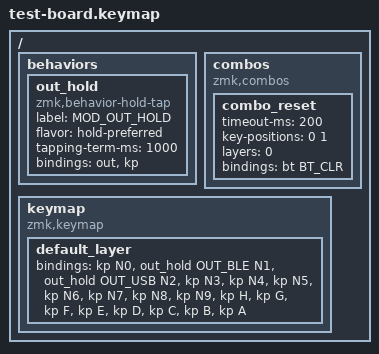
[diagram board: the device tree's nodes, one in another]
/*
 * Copyright (c) 2022 beta-tank
 * SPDX-License-Identifier: MIT
 */

 #include <behaviors.dtsi>
 #include <dt-bindings/zmk/keys.h>
 #include <dt-bindings/zmk/bt.h>
 #include <dt-bindings/zmk/outputs.h>

 /*

 Tap combo "0" and "1" for BT pairing reset

 LEGEND: KEYCODE | NRFMICRO_PIN (ARDUINO_PIN)

 - | RAW          (1) 0.06 | 0
 - | GND          (0) 0.08 | 1
 - | RST              GND  | -
 - | VCC              GND  | -
 A | 0.30 (21)    (2) 0.15 | 2
 B | 0.31 (20)    (3) 0.17 | 3
 C | 0.29 (19)    (4) 0.20 | 4
 D | 0.02 (18)    (5) 0.13 | 5
 E | 1.13 (15)    (6) 0.24 | 6
 F | 0.03 (14)    (7) 0.09 | 7
 G | 0.28 (16)    (8) 0.10 | 8
 H | 1.11 (10)    (9) 1.06 | 9 
 
 */
 
 / {
        behaviors {
                out_hold: out_hold {
                        compatible = "zmk,behavior-hold-tap";
                        label = "MOD_OUT_HOLD";
                        #binding-cells = <2>;
                        flavor = "hold-preferred";
                        tapping-term-ms = <1000>;
                        bindings = <&out>, <&kp>; //<&bt BT_CLR>
                };
        };
        combos {
                compatible = "zmk,combos";
                combo_reset {
                    timeout-ms = <200>;
                    key-positions = <0 1>;
                    layers = <0>;
                    bindings = <&bt BT_CLR>;
                };
        };
        keymap {
                compatible = "zmk,keymap";
                default_layer {
                        bindings = <
                                &kp N0
                                &out_hold OUT_BLE N1
                                &out_hold OUT_USB N2 
                                &kp N3
                                &kp N4 
                                &kp N5
                                &kp N6
                                &kp N7
                                &kp N8
                                &kp N9
                                &kp H 
                                &kp G 
                                &kp F 
                                &kp E 
                                &kp D 
                                &kp C 
                                &kp B 
                                &kp A
                                >;
                };
         };
 };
